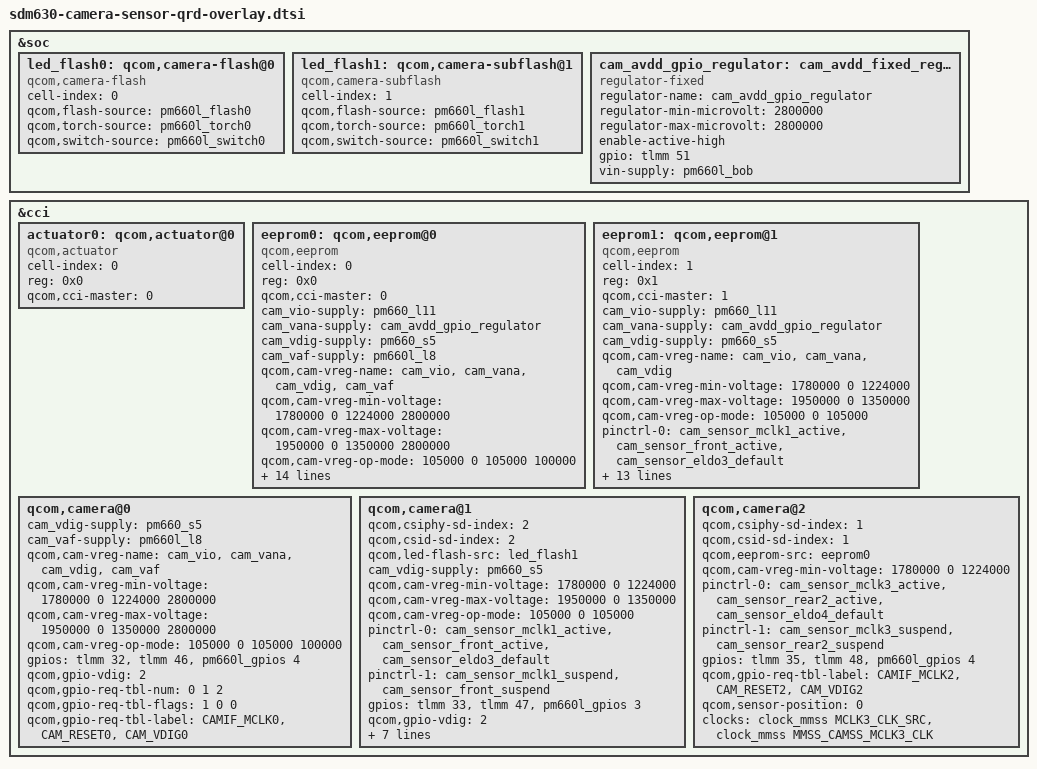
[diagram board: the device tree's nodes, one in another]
/*
 * Copyright (c) 2017, The Linux Foundation. All rights reserved.
 *
 * This program is free software; you can redistribute it and/or modify
 * it under the terms of the GNU General Public License version 2 and
 * only version 2 as published by the Free Software Foundation.
 *
 * This program is distributed in the hope that it will be useful,
 * but WITHOUT ANY WARRANTY; without even the implied warranty of
 * MERCHANTABILITY or FITNESS FOR A PARTICULAR PURPOSE.  See the
 * GNU General Public License for more details.
 */

&soc {
	/delete-node/ qcom,camera-flash;
	/delete-node/ cam_vaf_gpio_regulator;
	/delete-node/ cam_rear_dvdd_fixed_regulator;

	led_flash0: qcom,camera-flash@0 {
		cell-index = <0>;
		compatible = "qcom,camera-flash";
		qcom,flash-source = <&pm660l_flash0>;
		qcom,torch-source = <&pm660l_torch0>;
		qcom,switch-source = <&pm660l_switch0>;
		status = "ok";
	};

	led_flash1: qcom,camera-subflash@1 {
		cell-index = <1>;
		compatible = "qcom,camera-subflash";
		qcom,flash-source = <&pm660l_flash1>;
		qcom,torch-source = <&pm660l_torch1>;
		qcom,switch-source = <&pm660l_switch1>;
		status = "ok";
	};

	cam_avdd_gpio_regulator: cam_avdd_fixed_regulator {
		compatible = "regulator-fixed";
		regulator-name = "cam_avdd_gpio_regulator";
		regulator-min-microvolt = <2800000>;
		regulator-max-microvolt = <2800000>;
		enable-active-high;
		gpio = <&tlmm 51 GPIO_ACTIVE_HIGH>;
		vin-supply = <&pm660l_bob>;
	};
};

&cci {
	/delete-node/ qcom,actuator@1;
	/delete-node/ qcom,ois@0;
	/delete-node/ qcom,eeprom@2;

	/* Define actuator0 directly (no vreg needed) */
	actuator0: qcom,actuator@0 {
		cell-index = <0>;
		reg = <0x0>;
		compatible = "qcom,actuator";
		qcom,cci-master = <0>;
		status = "ok";
	};

	/* Define eeprom0 with correct supplies */
	eeprom0: qcom,eeprom@0 {
		cell-index = <0>;
		reg = <0x0>;
		compatible = "qcom,eeprom";
		qcom,cci-master = <0>;
		cam_vio-supply = <&pm660_l11>;
		cam_vana-supply = <&cam_avdd_gpio_regulator>;
		cam_vdig-supply = <&pm660_s5>;
		cam_vaf-supply = <&pm660l_l8>;
		qcom,cam-vreg-name = "cam_vio", "cam_vana", "cam_vdig", "cam_vaf";
		qcom,cam-vreg-min-voltage = <1780000 0 1224000 2800000>;
		qcom,cam-vreg-max-voltage = <1950000 0 1350000 2800000>;
		qcom,cam-vreg-op-mode = <105000 0 105000 100000>;
		pinctrl-names = "cam_default", "cam_suspend";
		pinctrl-0 = <&cam_sensor_mclk0_active &cam_sensor_rear_active>;
		pinctrl-1 = <&cam_sensor_mclk0_suspend &cam_sensor_rear_suspend>;
		gpios = <&tlmm 32 0>,
			<&tlmm 46 0>,
			<&pm660l_gpios 4 0>;
		qcom,gpio-reset = <1>;
		qcom,gpio-vdig = <2>;
		qcom,gpio-req-tbl-num = <0 1 2>;
		qcom,gpio-req-tbl-flags = <1 0 0>;
		qcom,gpio-req-tbl-label = "CAMIF_MCLK0",
					"CAM_RESET0",
					"CAM_VDIG0";
		clocks = <&clock_mmss MCLK0_CLK_SRC>,
			<&clock_mmss MMSS_CAMSS_MCLK0_CLK>;
		clock-names = "cam_src_clk", "cam_clk";
		qcom,clock-rates = <24000000 0>;
		status = "ok";
	};

	/* Define eeprom1 with correct supplies */
	eeprom1: qcom,eeprom@1 {
		cell-index = <1>;
		reg = <0x1>;
		compatible = "qcom,eeprom";
		qcom,cci-master = <1>;
		cam_vio-supply = <&pm660_l11>;
		cam_vana-supply = <&cam_avdd_gpio_regulator>;
		cam_vdig-supply = <&pm660_s5>;
		qcom,cam-vreg-name = "cam_vio", "cam_vana", "cam_vdig";
		qcom,cam-vreg-min-voltage = <1780000 0 1224000>;
		qcom,cam-vreg-max-voltage = <1950000 0 1350000>;
		qcom,cam-vreg-op-mode = <105000 0 105000>;
		pinctrl-names = "cam_default", "cam_suspend";
		pinctrl-0 = <&cam_sensor_mclk1_active
				&cam_sensor_front_active
				&cam_sensor_eldo3_default>;
		pinctrl-1 = <&cam_sensor_mclk1_suspend
				&cam_sensor_front_suspend>;
		gpios = <&tlmm 33 0>,
			<&tlmm 47 0>,
			<&pm660l_gpios 3 0>;
		qcom,gpio-reset = <1>;
		qcom,gpio-vdig = <2>;
		qcom,gpio-req-tbl-num = <0 1 2>;
		qcom,gpio-req-tbl-flags = <1 0 0>;
		qcom,gpio-req-tbl-label = "CAMIF_MCLK1",
					"CAM_RESET1",
					"CAM_VDIG1";
		qcom,sensor-position = <1>;
		clocks = <&clock_mmss MCLK1_CLK_SRC>,
			<&clock_mmss MMSS_CAMSS_MCLK1_CLK>;
		clock-names = "cam_src_clk", "cam_clk";
		qcom,clock-rates = <24000000 0>;
		status = "ok";
	};

	/* Camera 0 — Rear main */
	qcom,camera@0 {
		/delete-property/ qcom,special-support-sensors;
		/delete-property/ qcom,ois-src;

		cam_vdig-supply = <&pm660_s5>;
		cam_vaf-supply = <&pm660l_l8>;
		qcom,cam-vreg-name = "cam_vio", "cam_vana", "cam_vdig", "cam_vaf";
		qcom,cam-vreg-min-voltage = <1780000 0 1224000 2800000>;
		qcom,cam-vreg-max-voltage = <1950000 0 1350000 2800000>;
		qcom,cam-vreg-op-mode = <105000 0 105000 100000>;
		gpios = <&tlmm 32 0>,
			<&tlmm 46 0>,
			<&pm660l_gpios 4 0>;
		qcom,gpio-vdig = <2>;
		qcom,gpio-req-tbl-num = <0 1 2>;
		qcom,gpio-req-tbl-flags = <1 0 0>;
		qcom,gpio-req-tbl-label = "CAMIF_MCLK0",
					"CAM_RESET0",
					"CAM_VDIG0";
	};

	/* Camera 1 — Front */
	qcom,camera@1 {
		qcom,csiphy-sd-index = <2>;
		qcom,csid-sd-index = <2>;

		/delete-property/ qcom,actuator-src;

		qcom,led-flash-src = <&led_flash1>;
		cam_vdig-supply = <&pm660_s5>;
		qcom,cam-vreg-min-voltage = <1780000 0 1224000>;
		qcom,cam-vreg-max-voltage = <1950000 0 1350000>;
		qcom,cam-vreg-op-mode = <105000 0 105000>;
		pinctrl-0 = <&cam_sensor_mclk1_active
				&cam_sensor_front_active
				&cam_sensor_eldo3_default>;
		pinctrl-1 = <&cam_sensor_mclk1_suspend
				&cam_sensor_front_suspend>;
		gpios = <&tlmm 33 0>,
			<&tlmm 47 0>,
			<&pm660l_gpios 3 0>;
		qcom,gpio-vdig = <2>;
		qcom,gpio-req-tbl-num = <0 1 2>;
		qcom,gpio-req-tbl-flags = <1 0 0>;
		qcom,gpio-req-tbl-label = "CAMIF_MCLK1",
					"CAM_RESET1",
					"CAM_VDIG1";
		qcom,sensor-position = <1>;
		clocks = <&clock_mmss MCLK1_CLK_SRC>,
			<&clock_mmss MMSS_CAMSS_MCLK1_CLK>;
	};

	/* Camera 2 — Rear depth */
	qcom,camera@2 {
		qcom,csiphy-sd-index = <1>;
		qcom,csid-sd-index = <1>;
		qcom,eeprom-src = <&eeprom0>;
		qcom,cam-vreg-min-voltage = <1780000 0 1224000>;
		pinctrl-0 = <&cam_sensor_mclk3_active
				&cam_sensor_rear2_active
				&cam_sensor_eldo4_default>;
		pinctrl-1 = <&cam_sensor_mclk3_suspend
				&cam_sensor_rear2_suspend>;
		gpios = <&tlmm 35 0>,
			<&tlmm 48 0>,
			<&pm660l_gpios 4 0>;
		qcom,gpio-req-tbl-label = "CAMIF_MCLK2",
					"CAM_RESET2",
					"CAM_VDIG2";
		qcom,sensor-position = <0>;
		clocks = <&clock_mmss MCLK3_CLK_SRC>,
			<&clock_mmss MMSS_CAMSS_MCLK3_CLK>;
	};
};
